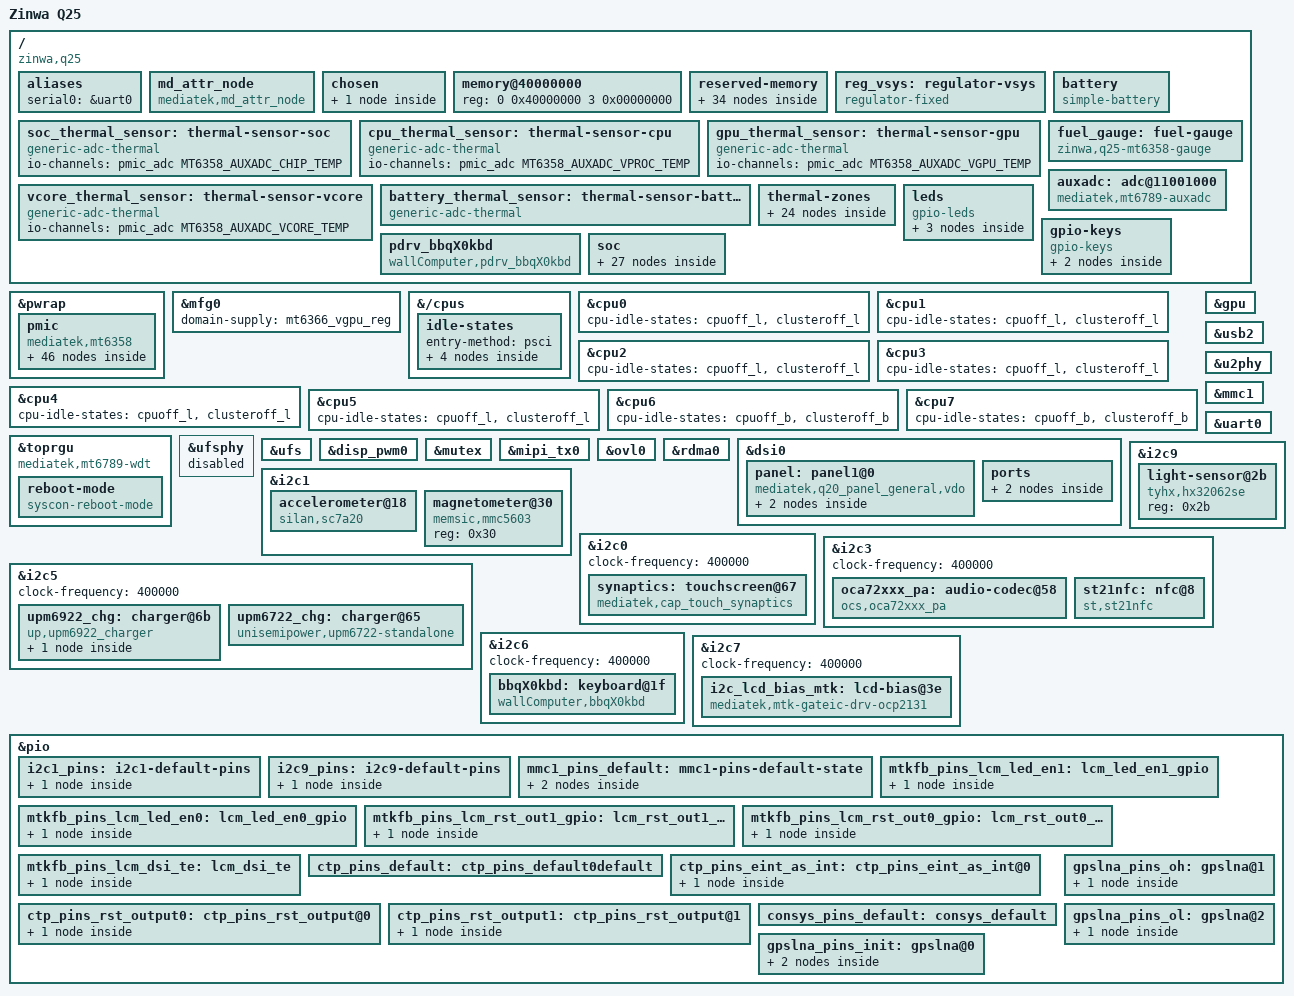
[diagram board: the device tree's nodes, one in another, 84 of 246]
// SPDX-License-Identifier: GPL-2.0
/*
 * Device Tree Source for Zinwa Q25 (Xelex Q20 v12 / MediaTek Helio G99 MT6789 / MT8781)
 *
 * Linux 7.3.3 devicetree with full Q25 peripheral wiring:
 * - BBQX0 Physical QWERTY Keyboard + Optical Trackpad (&i2c6 @ 0x1f + pdrv_bbqX0kbd)
 * - Synaptics S2716B 720x720 Capacitive Touchscreen (&i2c0 @ 0x67)
 * - Q20 720x720 60Hz MIPI DSI Video Panel (&dsi0) + OCP2131 Bias IC (&i2c7 @ 0x3e)
 * - UPM6922 Primary Charger + OTG VBUS (&i2c5 @ 0x6b) & UPM6722 Charge Pump (&i2c5 @ 0x65)
 * - OCA72xxx Smart Audio PA (&i2c3 @ 0x58)
 * - ST21NFC Controller (&i2c3 @ 0x08)
 * - RGB Status LEDs (GPIO 46/48/49) & Hardware Keys (PMIC Power/VolUp + GPIO 43 VolDown)
 * - Arm Mali-G57 MC2 GPU (Open-Source Panfrost)
 */

/dts-v1/;

#include <dt-bindings/input/input.h>
#include <dt-bindings/gpio/gpio.h>
#include <dt-bindings/iio/adc/mediatek,mt6358-auxadc.h>
#include <dt-bindings/regulator/mediatek,mt6397-regulator.h>
#include <dt-bindings/pinctrl/mediatek,mt6789-pinfunc.h>
#include <dt-bindings/thermal/thermal.h>
#include "mt6789.dtsi"

/ {
	model = "Zinwa Q25";
	chassis-type = "handset";
	compatible = "zinwa,q25", "mediatek,mt8781", "mediatek,mt6789";

	#address-cells = <2>;
	#size-cells = <2>;

	aliases {
		serial0 = &uart0;
	};

	md_attr_node {
		mediatek,md_product_name_model_id = <0xf0f0f0f>;
		mediatek,md_drdi_rf_set_idx = <0xf0f0f0f>;
		compatible = "mediatek,md_attr_node";
	};

	chosen: chosen {
		#address-cells = <2>;
		#size-cells = <2>;
		ranges;

		stdout-path = "serial0:921600n1";
		bootargs = "console=tty0 quiet loglevel=3 rd.udev.log_level=3 systemd.show_status=auto vt.global_cursor_default=0 panic=10 clk_ignore_unused pd_ignore_unused ramoops.mem_address=0x48090000 ramoops.mem_size=0xcf000 ramoops.record_size=0x1000 ramoops.console_size=0x40000 ramoops.ftrace_size=0 ramoops.pmsg_size=0 arm64.nomte";
		linux,initrd-start = <0 0x66f00000>;
		linux,initrd-end = <0 0x6890c19f>; /* 0x66f00000 + 18923935 (vendor) + 8 MiB (boot, padded) */
		atag,boot = <0x10000000 0x2080041 0x00 0x2000000>;
		atag,chipid = <0x18000000 0x8120000 0x8a0000 0xca0000 0x00>;
		atag,masp = <0x58000000 0x66080041 0x11000000 0x22000000 0x00 0x00 0x46be1a9a 0x939bac1e 0x84107e 0xfb18ab69 0x31413532 0x41333637 0x43423132 0x43343538 0x00 0x00 0x00 0x00 0x00 0x00 0x00 0x00>;

		framebuffer@ff97c000 {
			compatible = "simple-framebuffer";
			memory-region = <&framebuffer_mem>;
			reg = <0 0xff97c000 0 ((720 + 16) * 720 * 4)>;
			width = <720>;
			height = <720>;
			stride = <((720 + 16) * 4)>;
			format = "a8r8g8b8";
		};
	};

	memory@40000000 {
		device_type = "memory";
		reg = <0 0x40000000 3 0x00000000>;
	};

	reserved-memory {
		#address-cells = <2>;
		#size-cells = <2>;
		ranges;

		pstore@48090000 {
			reg = <0 0x48090000 0 0xe0000>;
			no-map;
		};

		framebuffer_mem: framebuffer@ff97c000 {
			reg = <0 0xff97c000 0 0x683000>;
			no-map;
		};

		ssmr_cma: ssmr-reserved-cma_memory@335000000 {
			reg = <0x3 0x35000000 0 0x0a000000>;
			no-map;
		};

		aee_debug_kinfo@48080000 {
			reg = <0 0x48080000 0 0x10000>;
			no-map;
		};

		minirdump@48170000 {
			reg = <0 0x48170000 0 0x10000>;
			no-map;
		};

		wifi_mem: wifi@bf000000 {
			reg = <0 0xbf000000 0 0x600000>;
			compatible = "shared-dma-pool";
			no-map;
		};

		emi_mem: consys_emi@7e000000 {
			reg = <0 0x7e000000 0 0x500000>;
			compatible = "mediatek,consys_emi_reserved";
			no-map;
		};

		sspm_ap_mem: sspm_ap@9f560000 {
			reg = <0 0x9f560000 0 0x110000>;
			compatible = "mediatek,sspm_ap-shared";
			no-map;
		};

		debug_met_res: debug_met_res@9f670000 {
			reg = <0 0x9f670000 0 0x800000>;
			compatible = "mediatek,debug_met_res-ram";
			no-map;
		};

		apmdc_mem: ap_md_c_smem@8c000000 {
			reg = <0 0x8c000000 0 0x16a0000>;
			compatible = "mediatek,ap_md_c_smem";
			no-map;
		};

		apmdnc_mem: ap_md_nc_smem@8e000000 {
			reg = <0 0x8e000000 0 0xe10000>;
			compatible = "mediatek,ap_md_nc_smem";
			no-map;
		};

		md_mem: md_mem@e5200000 {
			reg = <0 0xe5200000 0 0xe00000>;
			compatible = "mediatek,md_mem_usage";
			no-map;
		};

		md2_mem: md_mem2@e0800000 {
			reg = <0 0xe0800000 0 0x2c50000>;
			compatible = "mediatek,md_mem_usage";
			no-map;
		};

		md3_mem: md_mem3@dfc00000 {
			reg = <0 0xdfc00000 0 0x430000>;
			compatible = "mediatek,md_mem_usage";
			no-map;
		};

		md4_mem: md_mem4@de000000 {
			reg = <0 0xde000000 0 0x13f0000>;
			compatible = "mediatek,md_mem_usage";
			no-map;
		};

		ccci_mem: ccci_tag@bf7f0000 {
			reg = <0 0xbf7f0000 0 0x10000>;
			compatible = "mediatek,ccci_tag_mem";
			no-map;
		};

		scp_mem: scp_share@8f000000 {
			reg = <0 0x8f000000 0 0x7a0000>;
			compatible = "shared-dma-pool";
			no-map;
		};

		scp_res_mem: scp@bf800000 {
			reg = <0 0xbf800000 0 0x600000>;
			no-map;
		};

		atf_log_mem: atf_log@bfe00000 {
			reg = <0 0xbfe00000 0 0x200000>;
			no-map;
		};

		dfdmcu_mem: dfdmcu@ff000000 {
			reg = <0 0xff000000 0 0x100000>;
			no-map;
		};

		crypto_mem: crypto_hw@48401000 {
			reg = <0 0x48401000 0 0x1000>;
			no-map;
		};

		tee_mem: tee@70000000 {
			reg = <0 0x70000000 0 0x4600000>;
			no-map;
		};

		tee_sec_mem: tee_sec@7ea00000 {
			reg = <0 0x7ea00000 0 0x800000>;
			no-map;
		};

		gz_log_mem: gz_log@7f200000 {
			reg = <0 0x7f200000 0 0x41000>;
			no-map;
		};

		mcupm_mem: mcupm@7feb0000 {
			reg = <0 0x7feb0000 0 0x100000>;
			no-map;
		};

		log_store_mem: log_store@7ffbf000 {
			reg = <0 0x7ffbf000 0 0x40000>;
			no-map;
		};

		sspm_mem: sspm@9fe70000 {
			reg = <0 0x9fe70000 0 0x180000>;
			no-map;
		};

		bl31_mem: bl31@48200000 {
			reg = <0 0x48200000 0 0x200000>;
			no-map;
		};

		aee_lk_mem: aee_lk@50700000 {
			reg = <0 0x50700000 0 0x800000>;
			no-map;
		};

		unmap_mem: unmap@7f400000 {
			reg = <0 0x7f400000 0 0x400000>;
			no-map;
		};

		gz_mem: gz@7f800000 {
			reg = <0 0x7f800000 0 0x600000>;
			no-map;
		};

		mbist_mem: emi_mbist@7ffff000 {
			reg = <0 0x7ffff000 0 0x1000>;
			no-map;
		};

		dram_rk0_mem: dramc_rk0@1bffff000 {
			reg = <0x1 0xbffff000 0 0x1000>;
			no-map;
		};

		dram_rk1_mem: dramc_rk1@33ffff000 {
			reg = <0x3 0x3ffff000 0 0x1000>;
			no-map;
		};
	};

	reg_vsys: regulator-vsys {
		compatible = "regulator-fixed";
		regulator-name = "vsys";
		regulator-always-on;
		regulator-boot-on;
	};

	soc_thermal_sensor: thermal-sensor-soc {
		compatible = "generic-adc-thermal";
		#thermal-sensor-cells = <0>;
		io-channels = <&pmic_adc MT6358_AUXADC_CHIP_TEMP>;
		io-channel-names = "sensor-channel";
	};

	cpu_thermal_sensor: thermal-sensor-cpu {
		compatible = "generic-adc-thermal";
		#thermal-sensor-cells = <0>;
		io-channels = <&pmic_adc MT6358_AUXADC_VPROC_TEMP>;
		io-channel-names = "sensor-channel";
	};

	gpu_thermal_sensor: thermal-sensor-gpu {
		compatible = "generic-adc-thermal";
		#thermal-sensor-cells = <0>;
		io-channels = <&pmic_adc MT6358_AUXADC_VGPU_TEMP>;
		io-channel-names = "sensor-channel";
	};

	vcore_thermal_sensor: thermal-sensor-vcore {
		compatible = "generic-adc-thermal";
		#thermal-sensor-cells = <0>;
		io-channels = <&pmic_adc MT6358_AUXADC_VCORE_TEMP>;
		io-channel-names = "sensor-channel";
	};

	battery_thermal_sensor: thermal-sensor-battery {
		compatible = "generic-adc-thermal";
		#thermal-sensor-cells = <0>;
		io-channels = <&pmic_adc MT6358_AUXADC_BAT_TEMP>;
		io-channel-names = "sensor-channel";
		/*
		 * <millicelsius millivolts>: vendor 10 kOhm NTC (fg_temp_table,
		 * BAT_NTC_10) on a 24 kOhm pull-up to vbif28 (2.8 V):
		 * mV = 2800 * R / (24000 + R). 65..85 degC extrapolated (B=3472).
		 * An open/unbiased pin reads ~0 mV and still maps to 85 degC.
		 */
		temperature-lookup-table = <
			(-40000) 2494
			(-35000) 2410
			(-30000) 2311
			(-25000) 2198
			(-20000) 2071
			(-15000) 1935
			(-10000) 1790
			(-5000) 1639
			      0 1488
			   5000 1340
			  10000 1197
			  15000 1062
			  20000  938
			  25000  824
			  30000  720
			  35000  629
			  40000  548
			  45000  476
			  50000  414
			  55000  359
			  60000  312
			  65000  272
			  70000  238
			  75000  208
			  80000  182
			  85000  160
		>;
	};

	/*
	 * Battery data from the stock mtk_gauge node (vendor-dtb/stock-merged.dts):
	 *  - charge-full-design: g_Q_MAX[T1 = 25 degC][battery_id 0] = 2939 mAh
	 *  - OCV table: battery0_profile_t1 (25 degC; t2/10 degC is identical),
	 *    {mAh*10, OCV*10 mV, R, R_chg} rows resampled to 1 % steps of
	 *    g_Q_MAX (0 % lands at 3.401 V ~ SHUTDOWN_GAUGE0_VOLTAGE 3.4 V)
	 *  - internal resistance: median t1 R column (147 mOhm) + R_FG_VALUE
	 *    (1 mOhm) + FG_METER_RESISTANCE (7 mOhm); used only to estimate
	 *    OCV from VBAT under load
	 *  - voltage-max: mtk charger battery_cv 4.44 V; voltage-min:
	 *    SHUTDOWN_GAUGE0_VOLTAGE 3.4 V
	 */
	battery: battery {
		compatible = "simple-battery";
		device-chemistry = "lithium-ion";
		charge-full-design-microamp-hours = <2939000>;
		voltage-min-design-microvolt = <3400000>;
		voltage-max-design-microvolt = <4440000>;
		factory-internal-resistance-micro-ohms = <155000>;
		ocv-capacity-celsius = <25>;
		ocv-capacity-table-0 = <4393000 100 4379285 99 4368447 98 4357671 97
			4346895 96 4336118 95 4324464 94 4312708 93
			4300952 92 4289196 91 4277440 90 4265684 89
			4253928 88 4242172 87 4230416 86 4219355 85
			4207904 84 4196802 83 4185392 82 4174250 81
			4162880 80 4151697 79 4140921 78 4129612 77
			4118368 76 4107592 75 4096815 74 4085588 73
			4074263 72 4063897 71 4054100 70 4043934 69
			4032459 68 4020052 67 4008296 66 3996828 65
			3986320 64 3976276 63 3965499 62 3954930 61
			3944947 60 3934337 59 3924686 58 3915869 57
			3907052 56 3898320 55 3890483 54 3882690 53
			3875832 52 3868974 51 3862117 50 3856222 49
			3851287 48 3845466 47 3840490 46 3834710 45
			3829693 44 3824795 43 3820717 42 3815998 41
			3811880 40 3807202 39 3803043 38 3799124 37
			3795205 36 3791287 35 3788026 34 3784449 33
			3781148 32 3777612 31 3774270 30 3770775 29
			3767392 28 3764453 27 3761514 26 3758100 25
			3754636 24 3751697 23 3748344 22 3744425 21
			3740880 20 3737235 19 3732337 18 3726814 17
			3720248 16 3714370 15 3708241 14 3701152 13
			3693947 12 3689619 11 3687660 10 3685701 9
			3683741 8 3681564 7 3677291 6 3668838 5
			3651224 4 3614561 3 3563494 2 3495897 1
			3401233 0
		>;
	};

	/*
	 * MT6366 FGADC coulomb counter (drivers/power/q25_mt6358_gauge.c),
	 * registers the "battery" power supply. Sense resistor and CAR tune
	 * from the stock mtk_gauge node: R_FG_VALUE = <1> (mOhm),
	 * CAR_TUNE_VALUE = <101> (x10 -> 1010 per mille).
	 */
	fuel_gauge: fuel-gauge {
		compatible = "zinwa,q25-mt6358-gauge";
		mediatek,pmic = <&pmic>;
		monitored-battery = <&battery>;
		io-channels = <&pmic_adc MT6358_AUXADC_BATADC>;
		io-channel-names = "vbat";
		zinwa,fg-rsense-micro-ohms = <1000>;
		zinwa,fg-car-tune-permille = <1010>;
	};

	/* SoC AUXADC (vendor auxadc@11001000); used by the modem (md-channel) */
	auxadc: adc@11001000 {
		compatible = "mediatek,mt6789-auxadc", "mediatek,mt6765-auxadc";
		reg = <0 0x11001000 0 0x1000>;
		clocks = <&infracfg_ao CLK_IFRAO_AUXADC>;
		clock-names = "main";
		#io-channel-cells = <1>;
	};

	thermal-zones {
		soc-thermal {
			polling-delay-passive = <250>;
			polling-delay = <1000>;
			thermal-sensors = <&soc_thermal_sensor>;

			trips {
				soc_alert: trip-alert {
					temperature = <85000>;
					hysteresis = <2000>;
					type = "passive";
				};

				soc_crit: trip-crit {
					temperature = <110000>;
					hysteresis = <2000>;
					type = "critical";
				};
			};
		};

		cpu-thermal {
			polling-delay-passive = <250>;
			polling-delay = <1000>;
			thermal-sensors = <&cpu_thermal_sensor>;

			trips {
				/* throttle the A76 pair first to keep the chassis comfortable */
				cpu_warm: trip-warm {
					temperature = <70000>;
					hysteresis = <3000>;
					type = "passive";
				};

				cpu_alert: trip-alert {
					temperature = <85000>;
					hysteresis = <2000>;
					type = "passive";
				};

				cpu_crit: trip-crit {
					temperature = <110000>;
					hysteresis = <2000>;
					type = "critical";
				};
			};

			cooling-maps {
				map-warm {
					trip = <&cpu_warm>;
					cooling-device = <&cpu6 THERMAL_NO_LIMIT THERMAL_NO_LIMIT>,
					                 <&cpu7 THERMAL_NO_LIMIT THERMAL_NO_LIMIT>;
				};

				map0 {
					trip = <&cpu_alert>;
					cooling-device = <&cpu0 THERMAL_NO_LIMIT THERMAL_NO_LIMIT>,
					                 <&cpu1 THERMAL_NO_LIMIT THERMAL_NO_LIMIT>,
					                 <&cpu2 THERMAL_NO_LIMIT THERMAL_NO_LIMIT>,
					                 <&cpu3 THERMAL_NO_LIMIT THERMAL_NO_LIMIT>,
					                 <&cpu4 THERMAL_NO_LIMIT THERMAL_NO_LIMIT>,
					                 <&cpu5 THERMAL_NO_LIMIT THERMAL_NO_LIMIT>,
					                 <&cpu6 THERMAL_NO_LIMIT THERMAL_NO_LIMIT>,
					                 <&cpu7 THERMAL_NO_LIMIT THERMAL_NO_LIMIT>;
				};
			};
		};

		gpu-thermal {
			polling-delay-passive = <250>;
			polling-delay = <1000>;
			thermal-sensors = <&gpu_thermal_sensor>;

			trips {
				gpu_alert: trip-alert {
					temperature = <85000>;
					hysteresis = <2000>;
					type = "passive";
				};

				gpu_crit: trip-crit {
					temperature = <110000>;
					hysteresis = <2000>;
					type = "critical";
				};
			};

			cooling-maps {
				map0 {
					trip = <&gpu_alert>;
					cooling-device = <&gpu THERMAL_NO_LIMIT THERMAL_NO_LIMIT>;
				};
			};
		};

		vcore-thermal {
			polling-delay-passive = <500>;
			polling-delay = <2000>;
			thermal-sensors = <&vcore_thermal_sensor>;

			trips {
				vcore_crit: trip-crit {
					temperature = <110000>;
					hysteresis = <2000>;
					type = "critical";
				};
			};
		};

		battery-thermal {
			polling-delay-passive = <1000>;
			polling-delay = <2000>;
			thermal-sensors = <&battery_thermal_sensor>;

			trips {
				bat_crit: trip-crit {
					temperature = <60000>;
					hysteresis = <2000>;
					type = "critical";
				};
			};
		};
	};

	/* Zinwa Q25 RGB Notification LEDs */
	leds {
		compatible = "gpio-leds";

		led-red {
			label = "red";
			gpios = <&pio 46 GPIO_ACTIVE_HIGH>;
			default-state = "keep";
		};

		led-green {
			label = "green";
			gpios = <&pio 48 GPIO_ACTIVE_HIGH>;
			default-state = "keep";
		};

		led-blue {
			label = "blue";
			gpios = <&pio 49 GPIO_ACTIVE_HIGH>;
			default-state = "off";
		};
	};

	/* Volume Down GPIO key (KPD_KCOL0 on GPIO 66) */
	gpio-keys {
		compatible = "gpio-keys";

		key-volumedown {
			label = "Volume Down";
			gpios = <&pio 66 (GPIO_ACTIVE_LOW | GPIO_PULL_UP)>;
			linux,code = <KEY_VOLUMEDOWN>;
			debounce-interval = <15>;
			wakeup-source;
		};

		/* vendor kp@10010000 hw-init-map[1] = KEY_MUTE on KPD_KCOL1 (GPIO 67) */
		key-mute {
			label = "Mute";
			gpios = <&pio 67 (GPIO_ACTIVE_LOW | GPIO_PULL_UP)>;
			linux,code = <KEY_MUTE>;
			debounce-interval = <15>;
		};
	};

	/* Zinwa Q25 Keyboard & Optical Trackpad Power Sequencing / Firmware Control */
	pdrv_bbqX0kbd: pdrv_bbqX0kbd {
		compatible = "wallComputer,pdrv_bbqX0kbd";
		irq-gpio = <&pio 12 GPIO_ACTIVE_HIGH>;
		int-gpios = <&pio 12 GPIO_ACTIVE_HIGH>;
		power-vdd-gpios = <&pio 159 GPIO_ACTIVE_HIGH>;
		power-1v8-gpios = <&pio 157 GPIO_ACTIVE_HIGH>;
		power-2v8-gpios = <&pio 158 GPIO_ACTIVE_HIGH>;
		firmware-download-gpios = <&pio 47 GPIO_ACTIVE_HIGH>;
	};
};

&pwrap {
	status = "okay";

	pmic: pmic {
		compatible = "mediatek,mt6358";
		interrupt-controller;
		interrupts-extended = <&pio 137 IRQ_TYPE_LEVEL_HIGH>;
		#interrupt-cells = <2>;

		mt6366_regulator: mt6366-regulator {
			compatible = "mediatek,mt6366-regulator", "mediatek,mt6358-regulator";

			vsys-ldo1-supply = <&reg_vsys>;
			vsys-ldo2-supply = <&reg_vsys>;
			vsys-ldo3-supply = <&reg_vsys>;
			vsys-vs1-supply = <&reg_vsys>;
			vsys-vs2-supply = <&reg_vsys>;
			vsys-vdram1-supply = <&reg_vsys>;
			vsys-vcore-supply = <&reg_vsys>;
			vsys-vpa-supply = <&reg_vsys>;
			vsys-vproc11-supply = <&reg_vsys>;
			vsys-vproc12-supply = <&reg_vsys>;
			vsys-vgpu-supply = <&reg_vsys>;
			vsys-vmodem-supply = <&reg_vsys>;
			vs1-ldo1-supply = <&mt6366_vs1_reg>;
			vs2-ldo1-supply = <&mt6366_vdram1_reg>;
			vs2-ldo2-supply = <&mt6366_vs2_reg>;
			vs2-ldo3-supply = <&mt6366_vs2_reg>;

			mt6366_vdram1_reg: vdram1 {
				regulator-name = "vdram1";
				regulator-min-microvolt = <500000>;
				regulator-max-microvolt = <2087500>;
				regulator-ramp-delay = <12500>;
				regulator-enable-ramp-delay = <0>;
				regulator-always-on;
				regulator-allowed-modes = <MT6397_BUCK_MODE_AUTO
				                           MT6397_BUCK_MODE_FORCE_PWM>;
			};

			mt6366_vcore_reg: vcore {
				regulator-name = "vcore";
				regulator-min-microvolt = <500000>;
				regulator-max-microvolt = <1293750>;
				regulator-ramp-delay = <6250>;
				regulator-enable-ramp-delay = <200>;
				regulator-always-on;
				regulator-allowed-modes = <MT6397_BUCK_MODE_AUTO
				                           MT6397_BUCK_MODE_FORCE_PWM>;
			};

			/*
			 * vpa: owned by the modem (SIM / RF PA supply). No DT node, as in
			 * the vendor DT: with constraints, regulator late cleanup switched
			 * it off ~31 s after boot underneath the running modem.
			 */

			mt6366_vproc11_reg: vproc11 {
				regulator-name = "vproc11";
				regulator-min-microvolt = <500000>;
				regulator-max-microvolt = <1293750>;
				regulator-ramp-delay = <6250>;
				regulator-enable-ramp-delay = <200>;
				regulator-always-on;
				regulator-allowed-modes = <MT6397_BUCK_MODE_AUTO
				                           MT6397_BUCK_MODE_FORCE_PWM>;
			};

			mt6366_vproc12_reg: vproc12 {
				regulator-name = "vproc12";
				regulator-min-microvolt = <500000>;
				regulator-max-microvolt = <1293750>;
				regulator-ramp-delay = <6250>;
				regulator-enable-ramp-delay = <200>;
				regulator-always-on;
				regulator-allowed-modes = <MT6397_BUCK_MODE_AUTO
				                           MT6397_BUCK_MODE_FORCE_PWM>;
			};

			mt6366_vgpu_reg: vgpu {
				regulator-name = "vgpu";
				regulator-min-microvolt = <675000>;
				regulator-max-microvolt = <1293750>;
				regulator-ramp-delay = <6250>;
				regulator-enable-ramp-delay = <200>;
				regulator-always-on;
				regulator-boot-on;
				regulator-allowed-modes = <MT6397_BUCK_MODE_AUTO
				                           MT6397_BUCK_MODE_FORCE_PWM>;

				regulator-coupled-with = <&mt6366_vsram_gpu_reg>;
				regulator-coupled-max-spread = <100000>;
			};

			mt6366_vs2_reg: vs2 {
				regulator-name = "vs2";
				regulator-min-microvolt = <500000>;
				regulator-max-microvolt = <2087500>;
				regulator-ramp-delay = <12500>;
				regulator-enable-ramp-delay = <0>;
				regulator-always-on;
			};

			mt6366_vmodem_reg: vmodem {
				regulator-name = "vmodem";
				regulator-min-microvolt = <500000>;
				regulator-max-microvolt = <1293750>;
				regulator-ramp-delay = <6250>;
				regulator-enable-ramp-delay = <900>;
				regulator-always-on;
				regulator-allowed-modes = <MT6397_BUCK_MODE_AUTO
				                           MT6397_BUCK_MODE_FORCE_PWM>;
			};

			mt6366_vs1_reg: vs1 {
				regulator-name = "vs1";
				regulator-min-microvolt = <1000000>;
				regulator-max-microvolt = <2587500>;
				regulator-ramp-delay = <12500>;
				regulator-enable-ramp-delay = <0>;
				regulator-always-on;
			};

			/* LPDDR4X, always on */
			mt6366_vdram2_reg: vdram2 {
				regulator-name = "vdram2";
				regulator-min-microvolt = <600000>;
				regulator-max-microvolt = <1800000>;
				regulator-enable-ramp-delay = <3300>;
				regulator-always-on;
			};

			/*
			 * vsim1: owned by the modem (SIM / RF PA supply). No DT node, as in
			 * the vendor DT: with constraints, regulator late cleanup switched
			 * it off ~31 s after boot underneath the running modem.
			 */

			mt6366_vibr_reg: vibr {
				regulator-name = "vibr";
				regulator-min-microvolt = <1200000>;
				regulator-max-microvolt = <3300000>;
				regulator-enable-ramp-delay = <60>;
			};

			mt6366_vrf12_reg: vrf12 {
				regulator-name = "vrf12";
				regulator-min-microvolt = <1200000>;
				regulator-max-microvolt = <1200000>;
				regulator-enable-ramp-delay = <120>;
				regulator-always-on;
				regulator-boot-on;
			};

			mt6366_vio18_reg: vio18 {
				regulator-name = "vio18";
				regulator-min-microvolt = <1800000>;
				regulator-max-microvolt = <1800000>;
				regulator-enable-ramp-delay = <2700>;
				regulator-always-on;
				regulator-boot-on;
			};

			mt6366_vusb_reg: vusb {
				regulator-name = "vusb";
				regulator-min-microvolt = <3000000>;
				regulator-max-microvolt = <3100000>;
				regulator-enable-ramp-delay = <270>;
				regulator-always-on;
			};

			mt6366_vcamio_reg: vcamio {
				regulator-name = "vcamio";
				regulator-min-microvolt = <1800000>;
				regulator-max-microvolt = <1800000>;
				regulator-enable-ramp-delay = <325>;
			};

			mt6366_vcamd_reg: vcamd {
				regulator-name = "vcamd";
				regulator-min-microvolt = <900000>;
				regulator-max-microvolt = <1800000>;
				regulator-enable-ramp-delay = <325>;
			};

			mt6366_vcn18_reg: vcn18 {
				regulator-name = "vcn18";
				regulator-min-microvolt = <1800000>;
				regulator-max-microvolt = <1800000>;
				regulator-enable-ramp-delay = <270>;
				regulator-boot-on;
				regulator-always-on;
			};

			mt6366_vfe28_reg: vfe28 {
				regulator-name = "vfe28";
				regulator-min-microvolt = <2800000>;
				regulator-max-microvolt = <2800000>;
				regulator-enable-ramp-delay = <270>;
				regulator-boot-on;
				regulator-always-on;
			};

			mt6366_vsram_proc11_reg: vsram-proc11 {
				regulator-name = "vsram_proc11";
				regulator-min-microvolt = <500000>;
				regulator-max-microvolt = <1293750>;
				regulator-ramp-delay = <6250>;
				regulator-enable-ramp-delay = <240>;
				regulator-always-on;
			};

			mt6366_vcn28_reg: vcn28 {
				regulator-name = "vcn28";
				regulator-min-microvolt = <2800000>;
				regulator-max-microvolt = <2800000>;
				regulator-enable-ramp-delay = <270>;
				regulator-boot-on;
				regulator-always-on;
			};

			mt6366_vsram_others_reg: vsram-others {
				regulator-name = "vsram_others";
				regulator-min-microvolt = <500000>;
				regulator-max-microvolt = <1293750>;
				regulator-ramp-delay = <6250>;
				regulator-enable-ramp-delay = <240>;
				regulator-always-on;
			};

			mt6366_vsram_core_reg: vsram-core {
				regulator-name = "vsram_core";
				regulator-min-microvolt = <500000>;
				regulator-max-microvolt = <1293750>;
				regulator-enable-ramp-delay = <240>;
				regulator-always-on;
			};

			mt6366_vsram_gpu_reg: vsram-gpu {
				regulator-name = "vsram_gpu";
				regulator-min-microvolt = <775000>;
				regulator-max-microvolt = <1293750>;
				regulator-ramp-delay = <6250>;
				regulator-enable-ramp-delay = <240>;
				regulator-always-on;
				regulator-boot-on;

				regulator-coupled-with = <&mt6366_vgpu_reg>;
				regulator-coupled-max-spread = <100000>;
			};

			mt6366_vxo22_reg: vxo22 {
				regulator-name = "vxo22";
				regulator-min-microvolt = <2200000>;
				regulator-max-microvolt = <2200000>;
				regulator-enable-ramp-delay = <120>;
				regulator-always-on;
				regulator-boot-on;
			};

			mt6366_vefuse_reg: vefuse {
				regulator-name = "vefuse";
				regulator-min-microvolt = <1700000>;
				regulator-max-microvolt = <1900000>;
				regulator-enable-ramp-delay = <270>;
			};

			mt6366_vaux18_reg: vaux18 {
				regulator-name = "vaux18";
				regulator-min-microvolt = <1800000>;
				regulator-max-microvolt = <1800000>;
				regulator-enable-ramp-delay = <270>;
				regulator-always-on;
				regulator-boot-on;
			};

			mt6366_vmch_reg: vmch {
				regulator-name = "vmch";
				regulator-min-microvolt = <2900000>;
				regulator-max-microvolt = <3300000>;
				regulator-enable-ramp-delay = <60>;
				regulator-always-on;
			};

			mt6366_vbif28_reg: vbif28 {
				regulator-name = "vbif28";
				regulator-min-microvolt = <2800000>;
				regulator-max-microvolt = <2800000>;
				regulator-enable-ramp-delay = <270>;
				/*
				 * Pull-up supply of the battery NTC divider
				 * (vendor RBAT_PULL_UP_VOLT). Without it
				 * BAT_TEMP collapses and battery-thermal trips.
				 */
				regulator-always-on;
				regulator-boot-on;
			};

			mt6366_vsram_proc12_reg: vsram-proc12 {
				regulator-name = "vsram_proc12";
				regulator-min-microvolt = <500000>;
				regulator-max-microvolt = <1293750>;
				regulator-ramp-delay = <6250>;
				regulator-enable-ramp-delay = <240>;
				regulator-always-on;
			};

			mt6366_vcama1_reg: vcama1 {
				regulator-name = "vcama1";
				regulator-min-microvolt = <1800000>;
				regulator-max-microvolt = <3000000>;
				regulator-enable-ramp-delay = <325>;
				regulator-boot-on;
				regulator-always-on;
			};

			mt6366_vemc_reg: vemc {
				regulator-name = "vemc";
				regulator-min-microvolt = <2900000>;
				regulator-max-microvolt = <3300000>;
				regulator-enable-ramp-delay = <60>;
				regulator-boot-on;
			};

			mt6366_vio28_reg: vio28 {
				regulator-name = "vio28";
				regulator-min-microvolt = <2800000>;
				regulator-max-microvolt = <2800000>;
				regulator-enable-ramp-delay = <270>;
				regulator-boot-on;
				regulator-always-on;
			};

			mt6366_va12_reg: va12 {
				regulator-name = "va12";
				regulator-min-microvolt = <1200000>;
				regulator-max-microvolt = <1200000>;
				regulator-enable-ramp-delay = <270>;
				regulator-always-on;
			};

			mt6366_vrf18_reg: vrf18 {
				regulator-name = "vrf18";
				regulator-min-microvolt = <1800000>;
				regulator-max-microvolt = <1800000>;
				regulator-enable-ramp-delay = <120>;
			};

			mt6366_vcn33_reg: vcn33 {
				regulator-name = "vcn33";
				regulator-min-microvolt = <3300000>;
				regulator-max-microvolt = <3500000>;
				regulator-enable-ramp-delay = <270>;
			};

			mt6366_vcama2_reg: vcama2 {
				regulator-name = "vcama2";
				regulator-min-microvolt = <1800000>;
				regulator-max-microvolt = <3000000>;
				regulator-enable-ramp-delay = <325>;
				regulator-boot-on;
				regulator-always-on;
			};

			mt6366_vmc_reg: vmc {
				regulator-name = "vmc";
				regulator-min-microvolt = <1800000>;
				regulator-max-microvolt = <3300000>;
				regulator-enable-ramp-delay = <60>;
				regulator-boot-on;
				regulator-always-on;
			};

			mt6366_vldo28_reg: vldo28 {
				regulator-name = "vldo28";
				regulator-min-microvolt = <2800000>;
				regulator-max-microvolt = <2800000>;
				regulator-enable-ramp-delay = <270>;
				regulator-boot-on;
				regulator-always-on;
			};

			mt6366_vaud28_reg: vaud28 {
				regulator-name = "vaud28";
				regulator-min-microvolt = <2800000>;
				regulator-max-microvolt = <2800000>;
				regulator-enable-ramp-delay = <270>;
				regulator-boot-on;
				regulator-always-on;
			};

			/*
			 * vsim2: owned by the modem (SIM / RF PA supply). No DT node, as in
			 * the vendor DT: with constraints, regulator late cleanup switched
			 * it off ~31 s after boot underneath the running modem.
			 */

		};

		mt6358_rtc: rtc {
			compatible = "mediatek,mt6358-rtc";
		};

		pmic_adc: adc {
			compatible = "mediatek,mt6358-auxadc";
			#io-channel-cells = <1>;
		};

		mt6358codec: audio-codec {
			compatible = "mediatek,mt6358-sound";
			Avdd-supply = <&mt6366_vaud28_reg>;
			mediatek,dmic-mode = <0>;
		};

		/*
		 * Headset jack detection (PMIC ACCDET, EINT0, ACC mode); values
		 * from the stock DT accdet node. Driven by q25_mt6358_accdet.c
		 * in the out-of-tree audio module.
		 */
		accdet: accdet {
			compatible = "mediatek,mt6358-accdet";
			accdet-mic-vol = <6>;
			accdet-mic-mode = <1>;
			headset-eint-level-pol = <4>;
			headset-mode-setting = <0x500 0x500 0x01 0x1f0 0x800 0x800 0x20 0x44
						0x00 0x00 0x0e 0x00 0x00 0x00 0x00 0x00>;
			headset-three-key-threshold = <0 0x50 0xdc 0x190>;
			io-channels = <&pmic_adc MT6358_AUXADC_ACCDET>;
			io-channel-names = "pmic_accdet";
		};

		mt6358_keys: keys {
			compatible = "mediatek,mt6358-keys";

			power-off-time-sec = <10>;
			mediatek,long-press-mode = <1>;

			power {
				linux,keycodes = <KEY_POWER>;
				wakeup-source;
			};

			home {
				linux,keycodes = <KEY_VOLUMEUP>;
			};
		};
	};
};

&mfg0 {
	domain-supply = <&mt6366_vgpu_reg>;
};

/*
 * PSCI CPU idle states (values from the stock q20_v12_factory DT). Only the
 * CPU-off and cluster-off states are used; the deeper MCUSYS/system states
 * need the vendor SPM/MCUPM low-power drivers.
 */
&{/cpus} {
	idle-states {
		entry-method = "psci";

		cpuoff_l: cpu-off-l {
			compatible = "arm,idle-state";
			arm,psci-suspend-param = <0x00010001>;
			local-timer-stop;
			entry-latency-us = <50>;
			exit-latency-us = <100>;
			min-residency-us = <1600>;
		};

		cpuoff_b: cpu-off-b {
			compatible = "arm,idle-state";
			arm,psci-suspend-param = <0x00010002>;
			local-timer-stop;
			entry-latency-us = <50>;
			exit-latency-us = <100>;
			min-residency-us = <1400>;
		};

		clusteroff_l: cluster-off-l {
			compatible = "arm,idle-state";
			arm,psci-suspend-param = <0x01010101>;
			local-timer-stop;
			entry-latency-us = <100>;
			exit-latency-us = <250>;
			min-residency-us = <2100>;
		};

		clusteroff_b: cluster-off-b {
			compatible = "arm,idle-state";
			arm,psci-suspend-param = <0x01010102>;
			local-timer-stop;
			entry-latency-us = <100>;
			exit-latency-us = <250>;
			min-residency-us = <1900>;
		};
	};
};

&cpu0 { #cooling-cells = <2>; cpu-idle-states = <&cpuoff_l &clusteroff_l>; };
&cpu1 { #cooling-cells = <2>; cpu-idle-states = <&cpuoff_l &clusteroff_l>; };
&cpu2 { #cooling-cells = <2>; cpu-idle-states = <&cpuoff_l &clusteroff_l>; };
&cpu3 { #cooling-cells = <2>; cpu-idle-states = <&cpuoff_l &clusteroff_l>; };
&cpu4 { #cooling-cells = <2>; cpu-idle-states = <&cpuoff_l &clusteroff_l>; };
&cpu5 { #cooling-cells = <2>; cpu-idle-states = <&cpuoff_l &clusteroff_l>; };
&cpu6 { #cooling-cells = <2>; cpu-idle-states = <&cpuoff_b &clusteroff_b>; };
&cpu7 { #cooling-cells = <2>; cpu-idle-states = <&cpuoff_b &clusteroff_b>; };

/*
 * TOPRGU doubles as the reboot-mode syscon, exactly like the stock DT:
 * "systemctl reboot bootloader" lands in LK fastboot, "recovery" in recovery.
 */
&toprgu {
	compatible = "mediatek,mt6789-wdt", "mediatek,mt6589-wdt", "syscon", "simple-mfd";

	reboot-mode {
		compatible = "syscon-reboot-mode";
		offset = <0x24>;
		mask = <0x0f>;
		mode-charger = <0x01>;
		mode-recovery = <0x02>;
		mode-bootloader = <0x03>;
	};
};

/* Open-Source Panfrost GPU (Arm Mali-G57 MC2) */
&gpu {
	operating-points-v2 = <&gpu_opp_table>;
	mali-supply = <&mt6366_vgpu_reg>;
	assigned-clocks = <&topckgen CLK_TOP_MFG_PLL_SEL>;
	assigned-clock-parents = <&topckgen CLK_TOP_MFGPLL>;
	status = "okay";
};

&usb2 {
	status = "okay";
	dr_mode = "peripheral";
	maximum-speed = "high-speed";
};

&u2phy {
	status = "okay";
};

&mmc1 {
	status = "okay";

	pinctrl-names = "default", "state_uhs";
	pinctrl-0 = <&mmc1_pins_default>;
	pinctrl-1 = <&mmc1_pins_default>;

	bus-width = <4>;
	max-frequency = <200000000>;

	cap-sd-highspeed;
	sd-uhs-sdr12;
	sd-uhs-sdr25;
	sd-uhs-sdr50;
	sd-uhs-sdr104;
	sd-uhs-ddr50;

	cd-debounce-delay-ms = <0>;
	cd-gpios = <&pio 7 GPIO_ACTIVE_LOW>;

	vmmc-supply = <&mt6366_vmch_reg>;
	vqmmc-supply = <&mt6366_vmc_reg>;
};

&uart0 {
	status = "okay";
};

&ufsphy {
	status = "disabled";
};

&ufs {
	status = "okay";
	/delete-property/ phys;
	vcc-supply = <&mt6366_vemc_reg>;
	clocks = <&infracfg_ao CLK_IFRAO_UFS>,
	         <&infracfg_ao CLK_IFRAO_UFS_SAP_BCLK>,
	         <&infracfg_ao CLK_IFRAO_UNIPRO_TICK>,
	         <&infracfg_ao CLK_IFRAO_UNIPRO_SYSCLK>,
	         <&infracfg_ao CLK_IFRAO_UFS_AES>,
	         <&topckgen CLK_TOP_AES_UFSFDE>,
	         <&topckgen CLK_TOP_UFS>,
	         <&topckgen CLK_TOP_UFS_SEL>;
	clock-names = "ufs", "ufs_mp", "unipro_tick", "unipro_sys",
	              "ufs_aes", "ufsfde_ck", "ufs_ck", "ufs_sel";
	freq-table-hz = <0 0>, <0 0>, <0 0>, <0 0>,
	                <0 0>, <0 0>, <0 0>, <0 0>;
};

&disp_pwm0 {
	status = "okay";
};

&mutex {
	status = "okay";
};

&mipi_tx0 {
	status = "okay";
};

&ovl0 {
	status = "okay";
};

&rdma0 {
	status = "okay";
};

/* Q20 720x720 60Hz MIPI DSI Video Panel */
&dsi0 {
	status = "okay";
	#address-cells = <1>;
	#size-cells = <0>;

	panel: panel1@0 {
		compatible = "mediatek,q20_panel_general,vdo";
		reg = <0>;
		reset-gpios = <&pio 85 GPIO_ACTIVE_HIGH>;
		avdd-gpios = <&pio 156 GPIO_ACTIVE_HIGH>;
		backlight = <&i2c_lcd_bias_mtk>;
		board_name = "q20_v12";

		port {
			panel_in1: endpoint {
				remote-endpoint = <&dsi_out>;
			};
		};
	};

	ports {
		port {
			dsi_out: endpoint {
				remote-endpoint = <&panel_in1>;
			};
		};
	};
};

/*
 * I2C1 / I2C9: the stock firmware reads these sensors from the SCP sensor hub
 * (pins left in SCP_SCL0/SDA0 and SCP_SCL2/SDA2 mode by LK); mainline drives
 * them from the AP I2C controllers on the same pins instead.
 */
&i2c1 {
	clock-frequency = <400000>;
	pinctrl-names = "default";
	pinctrl-0 = <&i2c1_pins>;
	status = "okay";

	accelerometer@18 {
		compatible = "silan,sc7a20";
		reg = <0x18>;
		/* UNCALIBRATED: stock DT has no accelerometer direction metadata. */
		mount-matrix = "1", "0", "0",
		               "0", "1", "0",
		               "0", "0", "1";
	};

	magnetometer@30 {
		compatible = "memsic,mmc5603";
		reg = <0x30>;
	};
};

&i2c9 {
	clock-frequency = <400000>;
	pinctrl-names = "default";
	pinctrl-0 = <&i2c9_pins>;
	status = "okay";

	light-sensor@2b {
		compatible = "tyhx,hx32062se";
		reg = <0x2b>;
	};
};

/* I2C0: Synaptics S2716B 720x720 Capacitive Touchscreen */
&i2c0 {
	clock-frequency = <400000>;
	status = "okay";

	synaptics: touchscreen@67 {
		compatible = "mediatek,cap_touch_synaptics", "synaptics,dsx-i2c";
		reg = <0x67>;
		panel = <&panel>;	/* drm panel follower: sleep with the display */
		boot_mode = <&chosen>;
		synaptics,irq-gpio = <&pio 9 GPIO_ACTIVE_HIGH>;
		synaptics,irq-on-state = <0>;
		synaptics,reset-gpio = <&pio 152 GPIO_ACTIVE_HIGH>;
		synaptics,reset-on-state = <0>;
		synaptics,reset-active-ms = <20>;
		synaptics,reset-delay-ms = <200>;
		synaptics,power-gpio = <&pio 27 GPIO_ACTIVE_HIGH>;
		synaptics,power-on-state = <1>;
		synaptics,power-delay-ms = <200>;
		synaptics,input-device-name = "s2716b_ts";
	};
};

/* I2C3: OCA72xxx Smart Audio PA + ST21NFC Controller */
&i2c3 {
	clock-frequency = <400000>;
	status = "okay";

	oca72xxx_pa: audio-codec@58 {
		compatible = "ocs,oca72xxx_pa", "mediatek,k9_pa";
		reg = <0x58>;
		dev_index = <0>;
		status = "okay";
	};

	st21nfc: nfc@8 {
		compatible = "st,st21nfc";
		reg = <0x08>;
		interrupt-parent = <&pio>;
		interrupts = <1 IRQ_TYPE_LEVEL_LOW>;
		reset-gpios = <&pio 150 GPIO_ACTIVE_HIGH>;
		irq-gpios = <&pio 1 GPIO_ACTIVE_HIGH>;
		clkreq-gpios = <&pio 68 GPIO_ACTIVE_HIGH>;
		status = "okay";
	};
};

/* I2C5: UPM6922 Primary Charger + OTG VBUS & UPM6722 Standalone Charge Pump */
&i2c5 {
	clock-frequency = <400000>;
	status = "okay";

	upm6922_chg: charger@6b {
		compatible = "up,upm6922_charger";
		reg = <0x6b>;
		status = "okay";
		up,intr_gpio = <&pio 37 GPIO_ACTIVE_HIGH>;

		up,upm6922,ichg = <3000>;
		up,upm6922,iprechg = <180>;
		up,upm6922,iterm = <200>;
		up,upm6922,vreg = <4440>;
		up,upm6922,vindpm = <4600>;
		up,upm6922,boostv = <5000>;
		up,upm6922,boosti = <1200>;
		up,upm6922,vac-ovp = <14000>;

		boot_mode = <&chosen>;
		phys = <&u2port0 PHY_TYPE_USB2>;
		phy-names = "usb2-phy";
		io-channels = <&pmic_adc MT6358_AUXADC_VCDT>,
		              <&pmic_adc MT6358_AUXADC_BATADC>,
		              <&pmic_adc MT6358_AUXADC_BAT_TEMP>;
		io-channel-names = "vbus", "vbat", "bat_temp";

		upm6922_otg_vbus: otg {
			regulator-compatible = "upm6922,otg-vbus";
			regulator-name = "usb-otg-vbus";
		};
	};

	upm6722_chg: charger@65 {
		compatible = "unisemipower,upm6722-standalone";
		reg = <0x65>;
		status = "okay";
		upm6722,irq-gpio = <&pio 10 GPIO_ACTIVE_HIGH>;

		upm6722,bat-ocp-disable;
		upm6722,tsbus-flt-disable;
		upm6722,tsbat-flt-disable;
		upm6722,wdt-disable;
		upm6722,vbus-errhi-disable;
		upm6722,bat-ocp-alm-disable;

		upm6722,bat-ovp-threshold = <4525>;
		upm6722,bat-ocp-threshold = <8200>;
		upm6722,bus-ovp-threshold = <12000>;
		upm6722,bus-ocp-threshold = <5100>;
		upm6722,bus-ucp-threshold = <250>;
		upm6722,bus-rcp-threshold = <300>;
		upm6722,vac1-ovp-threshold = <18000>;
		upm6722,vac2-ovp-threshold = <18000>;
		upm6722,vout-ovp-threshold = <5000>;
		upm6722,tdie-flt-threshold = <140>;
		upm6722,tsbus-flt-threshold = <4102>;
		upm6722,tsbat-flt-threshold = <4102>;

		upm6722,bat-ovp-alm-threshold = <4510>;
		upm6722,bat-ocp-alm-threshold = <8000>;
		upm6722,bat-ucp-alm-threshold = <0>;
		upm6722,bus-ovp-alm-threshold = <11800>;
		upm6722,bus-ocp-alm-threshold = <5000>;
		upm6722,tdie-alm-threshold = <125>;

		upm6722,sense-resistor-mohm = <5>;
		upm6722,ss-timeout = <10000>;
		upm6722,wdt-set = <30000>;
		upm6722,chg-config-1 = <1>;
		upm6722,fsw-set = <5>;
		upm6722,freq-shift = <0>;
		upm6722,ibus-ucp-fall-dg-sel = <0>;

		upm6722,adc-enable;
		upm6722,adc-rate = <0>;
		upm6722,adc-avg = <0>;
		upm6722,adc-avg-init = <0>;
		upm6722,adc-sample-bit = <0>;
	};
};

/* I2C6: BBQX0 Physical QWERTY Keyboard & Optical Trackpad */
&i2c6 {
	clock-frequency = <400000>;
	status = "okay";

	bbqX0kbd: keyboard@1f {
		compatible = "wallComputer,bbqX0kbd";
		reg = <0x1f>;
		interrupt-parent = <&pio>;
		interrupts = <12 IRQ_TYPE_EDGE_FALLING>;
		vibr-supply = <&mt6366_vibr_reg>;
		panel = <&panel>;
	};
};

/* I2C7: OCP2131 LCD +/-5.8V Bias IC */
&i2c7 {
	clock-frequency = <400000>;
	status = "okay";

	i2c_lcd_bias_mtk: lcd-bias@3e {
		compatible = "mediatek,mtk-gateic-drv-ocp2131";
		reg = <0x3e>;
		id = <6>;
		gate-power-gpios = <&pio 84 GPIO_ACTIVE_HIGH>;
		status = "okay";
	};
};

&pio {
	i2c1_pins: i2c1-default-pins {
		pins-bus {
			pinmux = <PINMUX_GPIO132__FUNC_SCL1>,
			         <PINMUX_GPIO133__FUNC_SDA1>;
			bias-pull-up;
		};
	};

	i2c9_pins: i2c9-default-pins {
		pins-bus {
			pinmux = <PINMUX_GPIO148__FUNC_SCL9>,
			         <PINMUX_GPIO149__FUNC_SDA9>;
			bias-pull-up;
		};
	};

	mmc1_pins_default: mmc1-pins-default-state {
		pins-clk {
			pinmux = <PINMUX_GPIO71__FUNC_MSDC1_CLK>;
			drive-strength = <8>; /* vendor MTK_DRIVE_8mA (enum 3) */
			bias-pull-down = <MTK_PUPD_SET_R1R0_10>;
		};

		pins-cmd-dat {
			pinmux = <PINMUX_GPIO73__FUNC_MSDC1_DAT0>,
			         <PINMUX_GPIO74__FUNC_MSDC1_DAT1>,
			         <PINMUX_GPIO75__FUNC_MSDC1_DAT2>,
			         <PINMUX_GPIO76__FUNC_MSDC1_DAT3>,
			         <PINMUX_GPIO72__FUNC_MSDC1_CMD>;
			input-enable;
			drive-strength = <8>; /* vendor MTK_DRIVE_8mA (enum 3) */
			bias-pull-up = <MTK_PUPD_SET_R1R0_01>;
		};
	};

	mtkfb_pins_lcm_led_en1: lcm_led_en1_gpio {
		pins_cmd_dat {
			pinmux = <PINMUX_GPIO84__FUNC_GPIO84>;
			slew-rate = <1>;
			output-high;
		};
	};

	mtkfb_pins_lcm_led_en0: lcm_led_en0_gpio {
		pins_cmd_dat {
			pinmux = <PINMUX_GPIO84__FUNC_GPIO84>;
			slew-rate = <1>;
			output-low;
		};
	};

	mtkfb_pins_lcm_rst_out1_gpio: lcm_rst_out1_gpio {
		pins_cmd_dat {
			pinmux = <PINMUX_GPIO85__FUNC_GPIO85>;
			slew-rate = <1>;
			output-high;
		};
	};

	mtkfb_pins_lcm_rst_out0_gpio: lcm_rst_out0_gpio {
		pins_cmd_dat {
			pinmux = <PINMUX_GPIO85__FUNC_GPIO85>;
			slew-rate = <1>;
			output-low;
		};
	};

	mtkfb_pins_lcm_dsi_te: lcm_dsi_te {
		pins_cmd_dat {
			pinmux = <PINMUX_GPIO83__FUNC_DSI_TE>;
		};
	};

	ctp_pins_default: ctp_pins_default0default {
	};

	ctp_pins_eint_as_int: ctp_pins_eint_as_int@0 {
		pins_cmd_dat {
			pinmux = <PINMUX_GPIO9__FUNC_GPIO9>;
			slew-rate = <0>;
		};
	};

	ctp_pins_rst_output0: ctp_pins_rst_output@0 {
		pins_cmd_dat {
			pinmux = <PINMUX_GPIO152__FUNC_GPIO152>;
			slew-rate = <1>;
			output-low;
		};
	};

	ctp_pins_rst_output1: ctp_pins_rst_output@1 {
		pins_cmd_dat {
			pinmux = <PINMUX_GPIO152__FUNC_GPIO152>;
			slew-rate = <1>;
			output-high;
		};
	};

	consys_pins_default: consys_default {
	};

	/* vendor gps_l1_lna@0 (GPIO25) / gps_l5_lna@0 (GPIO87): LNAs off */
	gpslna_pins_init: gpslna@0 {
		pins_cmd_dat {
			pinmux = <PINMUX_GPIO25__FUNC_GPIO25>;
			slew-rate = <1>;
			output-low;
		};
		pins_l5 {
			pinmux = <PINMUX_GPIO87__FUNC_GPIO87>;
			slew-rate = <1>;
			output-low;
		};
	};

	gpslna_pins_oh: gpslna@1 {	/* vendor gps_l1_lna@2 */
		pins_cmd_dat {
			pinmux = <PINMUX_GPIO25__FUNC_GPIO25>;
			slew-rate = <1>;
			output-high;
		};
	};

	gpslna_pins_ol: gpslna@2 {	/* vendor gps_l1_lna@0 */
		pins_cmd_dat {
			pinmux = <PINMUX_GPIO25__FUNC_GPIO25>;
			slew-rate = <1>;
			output-low;
		};
	};
};

/ {
	soc {
		dpmaif: dpmaif@10014000 {
			compatible = "mediatek,dpmaif";
			reg = <0 0x10014000 0 0x1000>,
			      <0 0x10014400 0 0x1000>,
			      <0 0x1022d000 0 0x1000>,
			      <0 0x1022d100 0 0x1000>,
			      <0 0x1022d400 0 0x1000>,
			      <0 0x1022c000 0 0x1000>,
			      <0 0x1022e000 0 0x1000>;
			interrupts = <GIC_SPI 241 IRQ_TYPE_LEVEL_HIGH 0>;
			mediatek,dpmaif_capability = <6>;
			clocks = <&infracfg_ao CLK_IFRAO_DPMAIF_MAIN>;
			clock-names = "infra-dpmaif-clk";
			mediatek,dpmaif_ver = <1>;
			mediatek,chip_info = <6789>;
		};

		ccifdriver: ccifdriver@10209000 {
			compatible = "mediatek,ccci_ccif";
			reg = <0 0x10209000 0 0x1000>,
			      <0 0x1020a000 0 0x1000>;
			mediatek,sram_size = <512>;
			interrupts = <GIC_SPI 226 IRQ_TYPE_LEVEL_HIGH 0>,
			             <GIC_SPI 227 IRQ_TYPE_LEVEL_HIGH 0>;
			clocks = <&infracfg_ao CLK_IFRAO_CCIF_AP>,
			         <&infracfg_ao CLK_IFRAO_CCIF_MD>,
			         <&infracfg_ao CLK_IFRAO_CCIF1_AP>,
			         <&infracfg_ao CLK_IFRAO_CCIF1_MD>,
			         <&infracfg_ao CLK_IFRAO_CCIF4_MD>,
			         <&infracfg_ao CLK_IFRAO_CCIF5_MD>;
			clock-names = "infra-ccif-ap",
			              "infra-ccif-md",
			              "infra-ccif1-ap",
			              "infra-ccif1-md",
			              "infra-ccif4-md",
			              "infra-ccif5-md";
		};

		mddriver: mddriver {
			ccci,modem_info_v2 = <0x7fbf 0x00 0x28180000 0x00 0x3000000 0x1b000000 0x1000000 0x00 0x00 0x00 0x00 0x00>;
			md1_ccb_cap_gear = <1>;
			md1_ccb_gear_list = "1(2,20);2(2,10);3(0,0);4(2,30);6(2,50);11(2,2);12(2,62)";
			compatible = "mediatek,mddriver";
			mediatek,mdhif_type = <6>;
			mediatek,md_id = <0>;
			mediatek,ap_plat_info = <6789>;
			mediatek,md_generation = <6295>;
			mediatek,offset_epon_md1 = <0x24 0x06>;
			mediatek,cldma_capability = <6>;
			mediatek,power_flow_config = <0x12>;
			mediatek,srclken_o1 = <0x200000>;
			reg = <0 0x0d0cf000 0 0x1000>;
			interrupts = <GIC_SPI 110 IRQ_TYPE_EDGE_RISING 0>,
			             <GIC_SPI 226 IRQ_TYPE_LEVEL_HIGH 0>,
			             <GIC_SPI 227 IRQ_TYPE_LEVEL_HIGH 0>;
			power-domains = <&spm MT6789_POWER_DOMAIN_MD>;
			ccci-infracfg = <&infracfg_ao>;
			ccci-topckgen = <&topckgen>;
			ccci_spmsleep = <&scpsys>;
			md_vmodem-supply = <&mt6366_vmodem_reg>;
			md_vmodem = <825000 825000>;
			md_vsram-supply = <&mt6366_vsram_core_reg>;
			md_vsram = <825000 825000>;
			dvfsrc-vcore-supply = <&mt6366_vcore_reg>;
		};

		ccci_scp: ccci_scp {
			compatible = "mediatek,ccci_md_scp";
			reg = <0 0x1023c000 0 0x1000>,
			      <0 0x1023d000 0 0x1000>;
			clocks = <&infracfg_ao CLK_IFRAO_CCIF2_AP>,
			         <&infracfg_ao CLK_IFRAO_CCIF2_MD>;
			clock-names = "infra-ccif2-ap", "infra-ccif2-md";
		};

		md_auxadc: md_auxadc {
			compatible = "mediatek,md_auxadc";
			io-channels = <&auxadc 2>;	/* SoC AUXADC ch2, as vendor */
			io-channel-names = "md-channel";
		};

		gpio_usage_mapping: gpio_usage_mapping {
			compatible = "mediatek,gpio_usage_mapping";
			GPIO_SIM1_HOT_PLUG = <&pio 23 0>;
			GPIO_SIM2_HOT_PLUG = <&pio 24 0>;
			GPIO_SIM1_SCLK = <&pio 77 0>;
			GPIO_SIM1_SRST = <&pio 78 0>;
			GPIO_SIM1_SIO = <&pio 79 0>;
			GPIO_SIM2_SCLK = <&pio 80 0>;
			GPIO_SIM2_SRST = <&pio 81 0>;
			GPIO_SIM2_SIO = <&pio 82 0>;
			GPIO_FDD_BAND_SUPPORT_DETECT_1ST_PIN = <&pio 111 0>;
		};

		md1_sim1_hot_plug_eint: MD1_SIM1_HOT_PLUG_EINT {
			compatible = "mediatek,md1_sim1_hot_plug_eint-eint";
			interrupt-parent = <&pio>;
			interrupts = <0 4>;
			debounce = <0 10000>;
			dedicated = <0 0>;
			src_pin = <0 1>;
			sockettype = <0 0>;
			status = "okay";
		};

		md1_sim2_hot_plug_eint: MD1_SIM2_HOT_PLUG_EINT {
		};

		ap_ccif0@10209000 {
			compatible = "mediatek,ap_ccif0";
			reg = <0 0x10209000 0 0x1000>;
		};

		md_ccif0@1020a000 {
			compatible = "mediatek,md_ccif0";
			reg = <0 0x1020a000 0 0x1000>;
		};

		ap_ccif1@1020b000 {
			compatible = "mediatek,ap_ccif1";
			reg = <0 0x1020b000 0 0x1000>;
		};

		md_ccif1@1020c000 {
			compatible = "mediatek,md_ccif1";
			reg = <0 0x1020c000 0 0x1000>;
		};

		ap_ccif2@1023c000 {
			compatible = "mediatek,ap_ccif2";
			reg = <0 0x1023c000 0 0x1000>;
		};

		md_ccif2@1023d000 {
			compatible = "mediatek,md_ccif2";
			reg = <0 0x1023d000 0 0x1000>;
		};

		ap_ccif3@1023e000 {
			compatible = "mediatek,ap_ccif3";
			reg = <0 0x1023e000 0 0x1000>;
			interrupts = <GIC_SPI 231 IRQ_TYPE_LEVEL_HIGH 0>;
		};

		md_ccif3@1023f000 {
			compatible = "mediatek,md_ccif3";
			reg = <0 0x1023f000 0 0x1000>;
		};

		ap_ccif4@1024c000 {
			compatible = "mediatek,ap_ccif4";
			reg = <0 0x1024c000 0 0x1000>;
		};

		md_ccif4@1024d000 {
			compatible = "mediatek,md_ccif4";
			reg = <0 0x1024d000 0 0x1000>;
		};

		ap_ccif5@1025c000 {
			compatible = "mediatek,ap_ccif5";
			reg = <0 0x1025c000 0 0x1000>;
		};

		md_ccif5@1025d000 {
			compatible = "mediatek,md_ccif5";
			reg = <0 0x1025d000 0 0x1000>;
		};

		infra_dpmaif@1022c000 {
			compatible = "mediatek,infra_dpmaif";
			reg = <0 0x1022c000 0 0x1000>;
		};

		infra_dpmaif@1022d000 {
			compatible = "mediatek,infra_dpmaif";
			reg = <0 0x1022d000 0 0x1000>;
		};

		infra_dpmaif@1022e000 {
			compatible = "mediatek,infra_dpmaif";
			reg = <0 0x1022e000 0 0x1000>;
		};

		infra_dpmaif@1022f000 {
			compatible = "mediatek,infra_dpmaif";
			reg = <0 0x1022f000 0 0x1000>;
		};

		btif: btif@1100c000 {
			compatible = "mediatek,btif";
			reg = <0 0x1100c000 0 0x1000>,
			      <0 0x10217b00 0 0x80>,
			      <0 0x10217b80 0 0x80>;
			interrupts = <GIC_SPI 190 IRQ_TYPE_LEVEL_HIGH 0>,
			             <GIC_SPI 184 IRQ_TYPE_LEVEL_HIGH 0>,
			             <GIC_SPI 185 IRQ_TYPE_LEVEL_HIGH 0>;
			clocks = <&infracfg_ao CLK_IFRAO_BTIF>,
			         <&infracfg_ao CLK_IFRAO_AP_DMA>;
			clock-names = "btifc", "apdmac";
		};

		consys: consys@18002000 {
			compatible = "mediatek,mt6789-consys";
			#thermal-sensor-cells = <0>;
			#address-cells = <2>;
			#size-cells = <2>;
			reg = <0 0x18002000 0 0x1000>,
			      <0 0x10007000 0 0x0100>,
			      <0 0x10001000 0 0x1000>,
			      <0 0x10006000 0 0x1000>,
			      <0 0x18007000 0 0x1000>,
			      <0 0x180b1000 0 0x1000>,
			      <0 0x180a3000 0 0x1000>,
			      <0 0x180a5000 0 0x800>,
			      <0 0x180c1000 0 0x1000>,
			      <0 0x18004000 0 0x1000>,
			      <0 0x1024c000 0 0x40>,
			      <0 0x10003000 0 0x1000>;
			interrupts = <GIC_SPI 410 IRQ_TYPE_LEVEL_HIGH 0>,
			             <GIC_SPI 111 IRQ_TYPE_LEVEL_HIGH 0>,
			             <GIC_SPI 411 IRQ_TYPE_LEVEL_HIGH 0>;
			power-domains = <&spm MT6789_POWER_DOMAIN_CONN>;
			emi-addr = <0x7e000000>;
			emi-size = <0x500000>;
			emi-alignment = <0x1000000>;
			emi-max-addr = <0x80000000>;
			pmic = <&pmic>;
			vcn18-supply = <&mt6366_vcn18_reg>;
			vcn28-supply = <&mt6366_vcn28_reg>;
			vcn33_bt-supply = <&mt6366_vcn33_reg>;
			vcn33_wifi-supply = <&mt6366_vcn33_reg>;
			clocks = <&infracfg_ao CLK_IFRAO_CCIF4_AP>;
			clock-names = "ccif";
			pinctrl-names = "default", "gps_lna_state_init",
			                "gps_lna_state_oh", "gps_lna_state_ol";
			pinctrl-0 = <&consys_pins_default>;
			pinctrl-1 = <&gpslna_pins_init>;
			pinctrl-2 = <&gpslna_pins_oh>;
			pinctrl-3 = <&gpslna_pins_ol>;
			status = "okay";
		};

		wifi: wifi@18000000 {
			memory-region = <&wifi_mem>;
			compatible = "mediatek,wifi";
			reg = <0 0x18000000 0 0x100000>;
			interrupts = <GIC_SPI 409 IRQ_TYPE_LEVEL_HIGH 0>;
			emi-addr = <0x00>;
			emi-size = <0x600000>;
			emi-alignment = <0x1000000>;
			emi-max-addr = <0xc0000000>;
		};
	};
};
